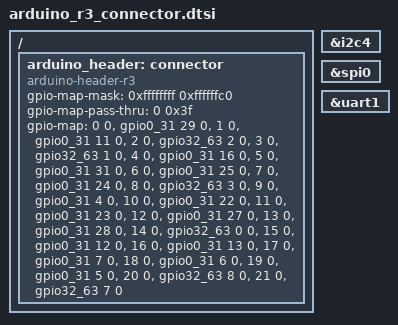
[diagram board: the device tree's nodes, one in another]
/*
 * SPDX-FileCopyrightText: Copyright The Zephyr Project Contributors
 *
 * SPDX-License-Identifier: Apache-2.0
 */

/ {
	arduino_header: connector {
		compatible = "arduino-header-r3";
		#gpio-cells = <2>;
		gpio-map-mask = <0xffffffff 0xffffffc0>;
		gpio-map-pass-thru = <0 0x3f>;
		gpio-map = <0 0 &gpio0_31 29 0>,	/* A0 */
			   <1 0 &gpio0_31 11 0>,	/* A1 */
			   <2 0 &gpio32_63 2 0>,	/* A2 */
			   <3 0 &gpio32_63 1 0>,	/* A3 */
			   <4 0 &gpio0_31 16 0>,	/* A4 */
			   <5 0 &gpio0_31 31 0>,	/* A5 */
			   <6 0 &gpio0_31 25 0>,	/* D0 */
			   <7 0 &gpio0_31 24 0>,	/* D1 */
			   <8 0 &gpio32_63 3 0>,	/* D2 */
			   <9 0 &gpio0_31 4 0>,	/* D3 */
			   <10 0 &gpio0_31 22 0>,	/* D4 */
			   <11 0 &gpio0_31 23 0>,	/* D5 */
			   <12 0 &gpio0_31 27 0>,	/* D6 */
			   <13 0 &gpio0_31 28 0>,	/* D7 */
			   <14 0 &gpio32_63 0 0>,	/* D8 */
			   <15 0 &gpio0_31 12 0>,	/* D9 */
			   <16 0 &gpio0_31 13 0>,	/* D10 */
			   <17 0 &gpio0_31 7 0>,	/* D11 */
			   <18 0 &gpio0_31 6 0>,	/* D12 */
			   <19 0 &gpio0_31 5 0>,	/* D13 */
			   <20 0 &gpio32_63 8 0>,	/* D14 */
			   <21 0 &gpio32_63 7 0>;	/* D15 */
	};
};

arduino_i2c: &i2c4 {};

arduino_spi: &spi0 {};

arduino_serial: &uart1 {};
